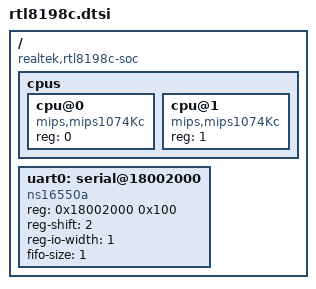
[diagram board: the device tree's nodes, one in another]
// SPDX-License-Identifier: GPL-2.0
/*
 * Realtek RTL8198C SoC device tree
 */

/dts-v1/;

/ {
	#address-cells = <1>;
	#size-cells = <1>;
	compatible = "realtek,rtl8198c-soc";

	cpus {
		#address-cells = <1>;
		#size-cells = <0>;

		cpu@0 {
			device_type = "cpu";
			compatible = "mips,mips1074Kc";
			reg = <0>;
		};

		cpu@1 {
			device_type = "cpu";
			compatible = "mips,mips1074Kc";
			reg = <1>;
		};
	};

	uart0: serial@18002000 {
		compatible = "ns16550a";
		reg = <0x18002000 0x100>;

		reg-shift = <2>;
		reg-io-width = <1>;
		fifo-size = <1>;

		status = "okay";
	};
};
